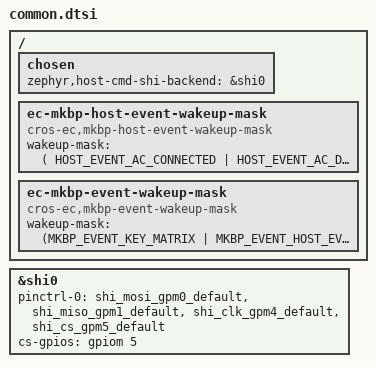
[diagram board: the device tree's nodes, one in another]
/* Copyright 2024 The ChromiumOS Authors
 * Use of this source code is governed by a BSD-style license that can be
 * found in the LICENSE file.
 */

#include <cros/integrated_fwid.dtsi>
#include <dt-bindings/wake_mask_event_defines.h>
#include <ite/it8xxx2-pinctrl-map.dtsi>

/ {
	chosen {
		zephyr,host-cmd-shi-backend = &shi0;
	};

	ec-mkbp-host-event-wakeup-mask {
		compatible = "cros-ec,mkbp-host-event-wakeup-mask";
		wakeup-mask = <(
			HOST_EVENT_AC_CONNECTED |
			HOST_EVENT_AC_DISCONNECTED |
			HOST_EVENT_LID_OPEN |
			HOST_EVENT_POWER_BUTTON |
			HOST_EVENT_HANG_DETECT |
			HOST_EVENT_MODE_CHANGE)>;
	};

	ec-mkbp-event-wakeup-mask {
		compatible = "cros-ec,mkbp-event-wakeup-mask";
		wakeup-mask = <(MKBP_EVENT_KEY_MATRIX |
				MKBP_EVENT_HOST_EVENT)>;
	};
};

&shi0 {
	status = "okay";
	pinctrl-0 = <&shi_mosi_gpm0_default &shi_miso_gpm1_default
		     &shi_clk_gpm4_default &shi_cs_gpm5_default>;
	pinctrl-names = "default";
	/* unused but needed by dt binding */
	cs-gpios = <&gpiom 5 GPIO_VOLTAGE_1P8>;
};
